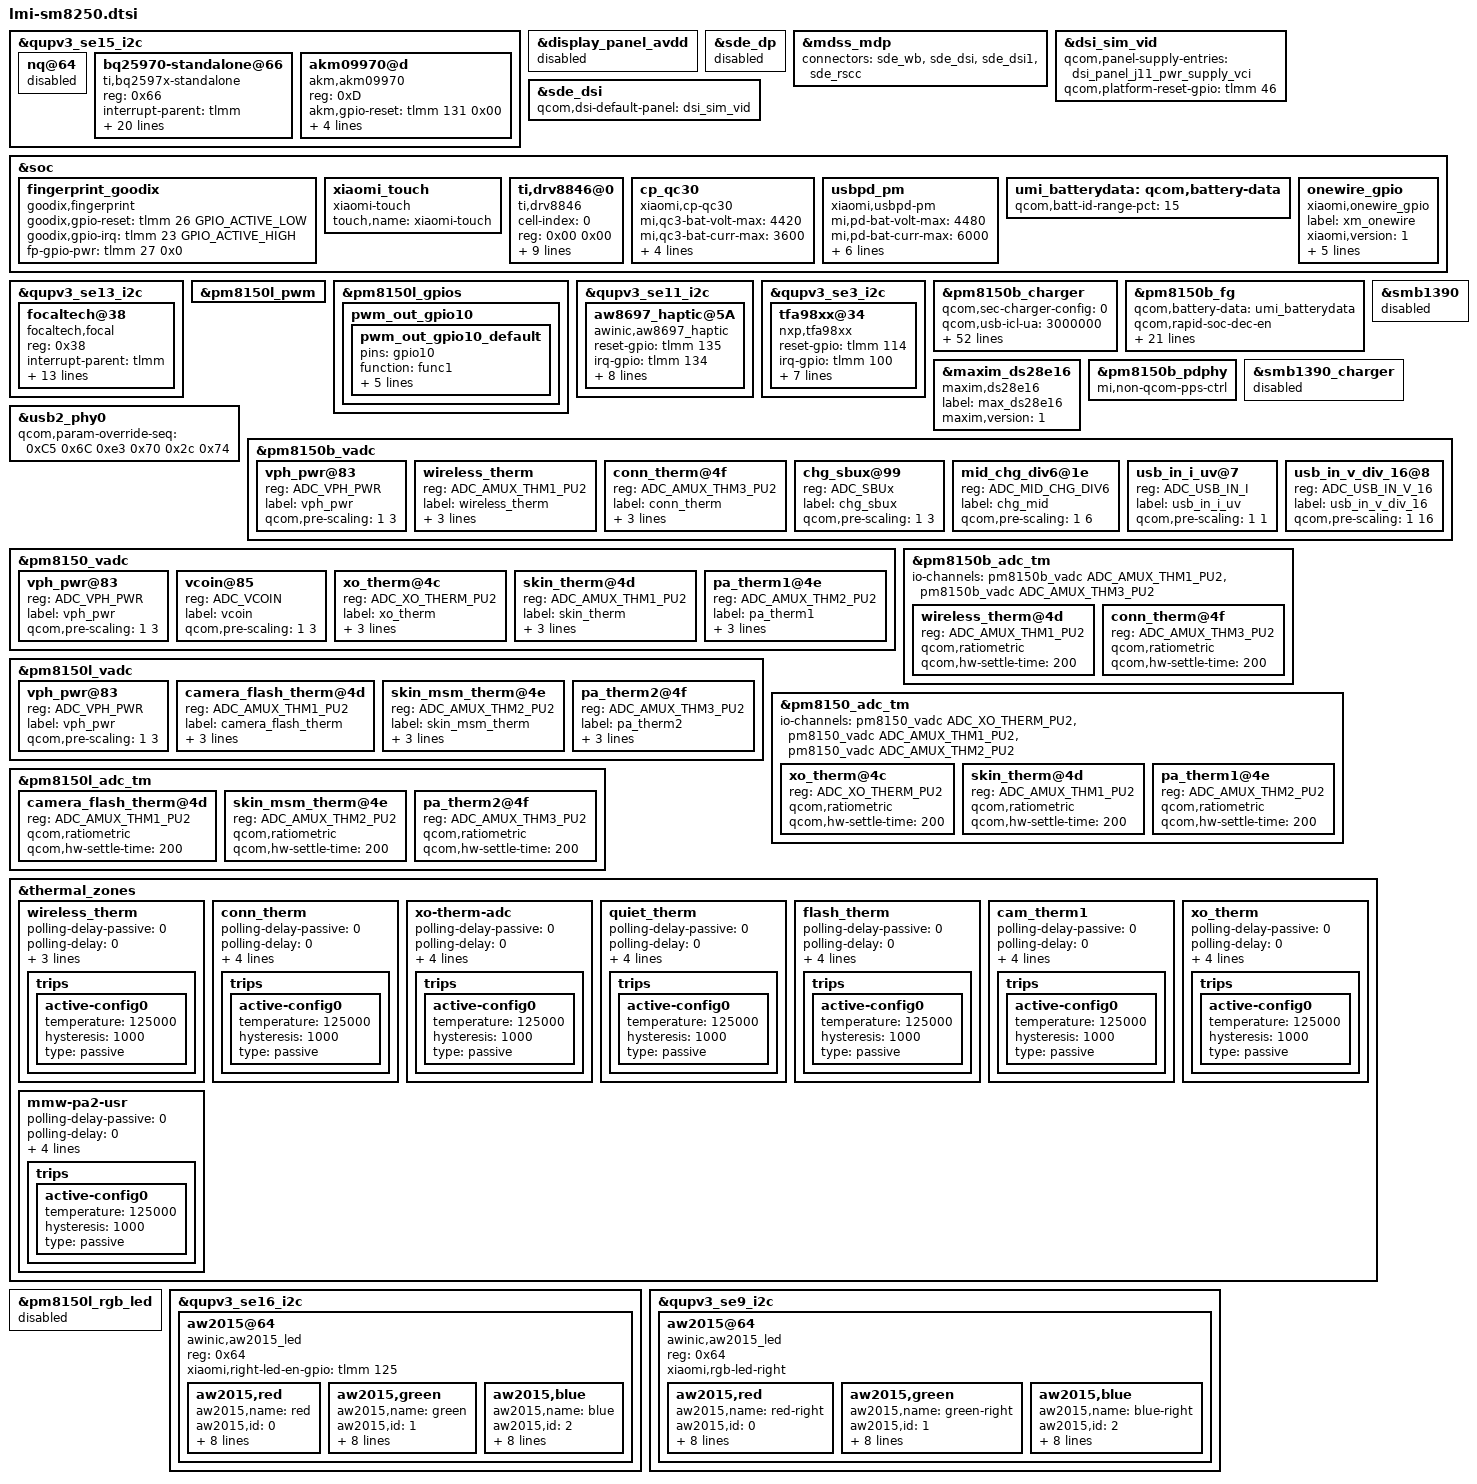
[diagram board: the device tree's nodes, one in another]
/*
this file is for attribution only of lmi
And public attribution of xiaomi platforms(like J1 and so and)
*/

#include "lmi-pinctrl.dtsi"
#include "xiaomi-sm8250-common.dtsi"
#include "lmi-audio-overlay.dtsi"

&qupv3_se15_i2c {
	status = "ok";
	nq@64 {
		status = "disabled";
	};
};

&display_panel_avdd {
	status = "disabled";
};

&sde_dp {
	status = "disabled";
};

&mdss_mdp {
	connectors = <&sde_wb &sde_dsi &sde_dsi1 &sde_rscc>;
};

&dsi_sim_vid {
	qcom,panel-supply-entries = <&dsi_panel_j11_pwr_supply_vci>;
	qcom,platform-reset-gpio = <&tlmm 46 0>;
};

&sde_dsi {
	/delete-property/ vdd-supply;
	/delete-property/ avdd-supply;
	qcom,dsi-default-panel = <&dsi_sim_vid>;
};

&soc {
    fingerprint_goodix {
		compatible = "goodix,fingerprint";
		goodix,gpio-reset = <&tlmm 26 GPIO_ACTIVE_LOW>;
		goodix,gpio-irq = <&tlmm 23 GPIO_ACTIVE_HIGH>;
		fp-gpio-pwr = <&tlmm 27 0x0>;
		status = "ok";
    };
};
&qupv3_se15_i2c {
	#address-cells = <1>;
	#size-cells = <0>;
	status = "ok";
	bq25970-standalone@66 {
		compatible = "ti,bq2597x-standalone";
		reg = <0x66>;
		interrupt-parent = <&tlmm>;
		interrupts = <157 0x2002>;
		pinctrl-names = "default";
		pinctrl-0 = <&bq2597x_master_int_default>;

		/*ti,bq2597x,bat-ovp-disable;*/
		ti,bq2597x,bat-ovp-alarm-disable;
		ti,bq2597x,bat-ocp-disable;
		ti,bq2597x,bat-ocp-alarm-disable;
		ti,bq2597x,bat-ucp-alarm-disable;
		ti,bq2597x,bat-ucp-disable;

		/*ti,bq2597x,bus-ovp-alarm-disable;
		ti,bq2597x,bus-ocp-disable;
		ti,bq2597x,bus-ocp-alarm-disable;*/
		ti,bq2597x,bat-therm-disable;
		ti,bq2597x,bus-therm-disable;
		ti,bq2597x,die-therm-disable;

		ti,bq2597x,bat-ovp-threshold = <4525>;
		ti,bq2597x,bat-ovp-alarm-threshold = <4525>;
		//ti,bq2597x,bat-ocp-threshold = <8000>;
		//ti,bq2597x,bat-ocp-alarm-threshold = <7500>;

		ti,bq2597x,bus-ovp-threshold = <12000>;
		ti,bq2597x,bus-ovp-alarm-threshold = <11000>;
		ti,bq2597x,bus-ocp-threshold = <3750>;
		ti,bq2597x,bus-ocp-alarm-threshold = <3500>;

		//ti,bq2597x,bat-ucp-alarm-threshold = <2000>;

		ti,bq2597x,bat-therm-threshold = <0x15>;/*4.1%*/
		ti,bq2597x,bus-therm-threshold = <0x15>;/*4.1%*/
		ti,bq2597x,die-therm-threshold = <145>;

		ti,bq2597x,ac-ovp-threshold = <14>;
		//ti,bq2597x,sense-resistor-mohm = <2>;
	};
};

&qupv3_se13_i2c {
	status = "ok";
	focaltech@38 {
		compatible = "focaltech,focal";
		reg = <0x38>;
		interrupt-parent = <&tlmm>;
		interrupts = <39 0x2002>;
		/* vddio-supply = <&pm8150a_l1>; */
		avdd-supply = <&pm8150a_l1>; //1v8
		focaltech,vdd-gpio = <&tlmm 72 0x0>;//3v
		focaltech,avdd-load = <300000>;
		focaltech,reset-gpio = <&tlmm 38 0x01>;
		focaltech,irq-gpio = <&tlmm 39 0x02>;
		focaltech,max-touch-number = <10>;
		focaltech,display-coords = <0 0 1080 2400>;
		focaltech,reset-when-resume;
		focaltech,lockdown-info-addr = <0x1E000>;
		focaltech,open-min = <2700>;
		pinctrl-names = "pmx_tp_active", "pmx_tp_suspend";
		pinctrl-0 = <&tp_active>;
		pinctrl-1 = <&tp_int_suspend &tp_reset_suspend>;
		/* focaltech,have-key; */
	};
};

&qupv3_se15_i2c {
        status = "ok";

        akm09970@d {
                compatible = "akm,akm09970";
                reg = <0xD>;
                akm,gpio-reset = <&tlmm 131 0x00>;
                akm,gpio-irq = <&tlmm 133 0x00>;
                vdd-supply = <&pm8150a_l8>;

                pinctrl-names = "akm09970_gpio_active", "akm09970_gpio_suspend";
                pinctrl-0 = <&akm_irq_active &akm_reset_active>;
                pinctrl-1 = <&akm_irq_suspend &akm_reset_suspend>;
                status = "ok";
        };
};

&pm8150l_pwm {
	status = "ok";
};

&soc{
	xiaomi_touch {
		compatible = "xiaomi-touch";
		status = "ok";
		touch,name = "xiaomi-touch";
	};

	ti,drv8846@0 {
		compatible = "ti,drv8846";
		cell-index = <0>;
		reg = <0x00 0x00>;
		pwms = <&pm8150l_pwm 1 1000000>;
		motor,gpio-mode0 = <&tlmm 158 0x00>;
		motor,gpio-mode1 = <&tlmm 154 0x00>;
		motor,gpio-sleep = <&tlmm 70 0x00>;
		motor,gpio-dir = <&tlmm 137 0x00>;
		motor,gpio-pwren = <&tlmm 153 0x00>;
		motor,step-mode = <2>;

		pinctrl-names = "default";
		pinctrl-0 = <&pwm_out_gpio10_default &motor_gpio_default>;
		status = "ok";
	};
};

&pm8150l_gpios {
	pwm_out_gpio10 {
		pwm_out_gpio10_default: pwm_out_gpio10_default {
			pins = "gpio10";
			function = "func1";
			bias-disable;
			power-source = <1>;
			output-low;
			qcom,drive-strength = <3>;
			drive-push-pull;
		};
	};
};

&qupv3_se11_i2c {
	status = "ok";
	aw8697_haptic@5A {
		compatible = "awinic,aw8697_haptic";
		reset-gpio = <&tlmm 135 0>;
		irq-gpio = <&tlmm 134 0>;
		vib_bst_vol_ram = < 0x11 >;
		vib_cont_drv_lev = < 106 >;
		vib_cont_drv_lvl_ov = < 106 >;
		vib_cont_td = < 0xef >;
		vib_tset = < 0x1a >;
		pinctrl-names = "aw8697_reset_reset","aw8697_reset_active","aw8697_interrupt_active";
		pinctrl-0 = <&msm_gpio_135>;
		pinctrl-1 = <&msm_gpio_135_output_high>;
		pinctrl-2 = <&msm_gpio_134>;
		status = "ok";
	};
};

&qupv3_se3_i2c {
	status = "ok";
	tfa98xx@34 {
		compatible = "nxp,tfa98xx";
		reset-gpio = <&tlmm 114 0>;
		irq-gpio = <&tlmm 100 0>;
		interrupt-parent = <&tlmm>;
		interrupts = <100 0>;
		interrupt-names = "smartpa_irq";
		pinctrl-names = "default", "sleep";
		pinctrl-0 = <&smartpa_int_active &smartpa_enable_active>;
		pinctrl-1 = <&smartpa_int_suspend &smartpa_enable_suspend>;
		reg = <0x34>;
		status = "ok";
	};
};

&pm8150b_charger {
	status = "ok";
	qcom,sec-charger-config = <0>;
	qcom,usb-icl-ua = <3000000>;
	qcom,fcc-max-ua = <6000000>;
	qcom,fv-max-uv = <4480000>;
	qcom,non-fcc-fv-max-uv = <4450000>;
	qcom,dc-icl-ua = <1000000>;
	qcom,auto-recharge-soc = <99>;
	qcom,chg-term-src = <1>;
	qcom,chg-term-current-ma = <(-220)>;
	//qcom,step-charging-enable;
	qcom,sw-jeita-enable;
	qcom,chg-warm-th= <480>;
	qcom,chg-cool-th= <150>;
	//qcom,suspend-input-on-debug-batt;
	qcom,usbpd-phandle = <&pm8150b_pdphy>;
	qcom,battery-data = <&umi_batterydata>;
	mi,six-pin-step-chg-params = <4250000  6000000
				4450000  5400000
				4480000  3680000>;
	mi,six-pin-step-chg;
	mi,six-pin-soc-th = <22>;
	mi,fcc-batt-unverify-ua = <2000000>;
	mi,support-ffc;
	qcom,lpd-disable;
	mi,use-bq-pump;
	qcom,disable-suspend-on-collapse;
	qcom,distinguish-qc-class-ab;
	qcom,support-conn-therm;
	vbus-disable-gpio = <&tlmm 152 GPIO_ACTIVE_HIGH>;
	pinctrl-names = "default", "vbus_disable_active", "vbus_disable_suspend";
	pinctrl-0 = <&vbus_disable_suspend>;
	pinctrl-1 = <&vbus_disable_active>;
	pinctrl-2 = <&vbus_disable_suspend>;
	io-channels = <&pm8150b_vadc ADC_USB_IN_V_16>,
			<&pm8150b_vadc ADC_MID_CHG_DIV6>,
			<&pm8150b_vadc ADC_USB_IN_I>,
			<&pm8150b_vadc ADC_SBUx>,
			<&pm8150b_vadc ADC_VPH_PWR>,
			<&pm8150b_vadc ADC_AMUX_THM3_PU2>,
			<&pm8150b_vadc ADC_CHG_TEMP>;
	io-channel-names = "usb_in_voltage",
			"mid_voltage",
			"usb_in_current",
			"sbux_res",
			"vph_voltage",
			"conn_temp",
			"chg_temp";
	qcom,thermal-mitigation = <3000000 2800000 2600000 2400000 2200000 2100000 2000000
				   1800000 1600000 1500000 1400000 1200000 1000000 900000
				   800000 500000>;
	qcom,thermal-mitigation-icl
				= <2800000 2700000 2600000 2400000 2200000 2100000 2000000
				   1800000 1600000 1500000 1400000 1300000 1200000 1100000
				   950000 750000>;
	qcom,thermal-mitigation-dcp
				= <1800000 1800000 1800000 1800000 1800000 1800000 1800000
				   1800000 1800000 1700000 1600000 1400000 1200000 1100000
				   1100000 1000000>;
	qcom,thermal-mitigation-qc2
				= <1500000 1500000 1500000 1500000 1450000 1400000 1350000
				   1300000 1150000 1100000 1000000 900000 850000 750000
				   650000 500000>;
	qcom,thermal-fcc-qc3-normal
				= <3200000 3000000 2800000 2600000 2500000 2400000 2300000
				   2200000 2100000 1800000 1600000 1400000 1200000 1000000
				   750000 750000>;
	qcom,thermal-fcc-qc3-cp
				= <4800000 4600000 4400000 4200000 4000000 3800000 3600000
				   3400000 3000000 2600000 2400000 2200000 2000000 1300000
				   1000000 700000>;
	qcom,thermal-fcc-qc3-classb-cp
				= <5100000 4700000 4300000 4000000 3600000 3500000 3400000
				   3400000 3400000 3200000 2500000 2200000 2000000 1300000
				   1000000 700000>;
	qcom,thermal-mitigation-pd-base
				= <3000000 2800000 2600000 2400000 2200000 2000000 1800000
				   1600000 1600000 1400000 1200000 1100000 1050000 1000000
				   950000 500000>;
	qcom,thermal-fcc-pps-bq
				= <6000000 5700000 5400000 5200000 4800000 4600000 4400000
				   4200000 3800000 3400000 3000000 2600000 2000000 1000000
				   700000 500000>;
};

&pm8150b_fg {
	qcom,battery-data = <&umi_batterydata>;
	qcom,rapid-soc-dec-en;
	qcom,five-pin-battery;
	qcom,soc-hi-res;
	qcom,sun-profile-only;
	qcom,soc_decimal_rate = <
		0  38
		10 35
		20 33
		30 33
		40 33
		50 33
		60 33
		70 30
		80 25
		90 20
		95 10 >;
	qcom,fg-sys-term-current = <(-300)>;
	qcom,fg-ffc-sys-term-current = <(-900)>;
	qcom,ki-coeff-low-chg = <315>;
	qcom,ki-coeff-med-chg = <183>;
	qcom,fg-cutoff-voltage = <3400>;
	qcom,fg-cutoff-current = <200>;
	qcom,fg-empty-voltage = <3100>;
	qcom,fg-batt-temp-hyst = <1>;
	qcom,fg-batt-temp-delta = <6>;
	qcom,soc-scale-vbatt-mv = <3600>;
	qcom,shutdown-delay-enable;
	qcom,fg-force-load-profile;
	qcom,ki-coeff-chg-med-hi-thresh-ma = <1000>;
	qcom,ki-coeff-chg-low-med-thresh-ma = <500>;
	qcom,ffc-ki-coeff-chg-med-hi-thresh-ma = <3900>;
	qcom,ffc-ki-coeff-chg-low-med-thresh-ma = <3500>;
};

&soc {
	cp_qc30 {
		compatible = "xiaomi,cp-qc30";
		status = "ok";
		mi,qc3-bat-volt-max = <4420>;
		mi,qc3-bat-curr-max = <3600>;
		mi,qc3-bus-volt-max = <12000>;
		mi,qc3-bus-curr-max = <2100>;
		mi,qc3-battery-warm-th = <480>;
		mi,use-qcom-gauge;
		//mi,cp-sec-enable;
	};

	usbpd_pm {
		compatible = "xiaomi,usbpd-pm";
		status = "ok";
		mi,pd-bat-volt-max = <4480>;
		mi,pd-bat-curr-max = <6000>;
		mi,pd-bus-volt-max = <12000>;
		mi,pd-bus-curr-max = <3000>;
		mi,pd-bus-curr-compensate  = <0>;
		mi,pd-non-ffc-bat-volt-max = <4450>;
		mi,pd-battery-warm-th = <480>;
		mi,use-qcom-gauge;
		//mi,cp-sec-enable;
	};

	umi_batterydata: qcom,battery-data {
		qcom,batt-id-range-pct = <15>;
		#include "fg-gen4-batterydata-lmi-sun-4700mah.dtsi"
	};

	onewire_gpio: onewire_gpio {
		compatible = "xiaomi,onewire_gpio";
		label = "xm_onewire";
		xiaomi,version = <1>;
		xiaomi,ow_gpio = <&tlmm 9 0x00>;
		mi,onewire-gpio-cfg-addr = <0x0F909000 0x4>;
		xiaomi,gpio_number = <9>;
		pinctrl-names = "onewire_active", "onewire_sleep";
		pinctrl-0 = <&onewire_gpio_active>;
		pinctrl-1 = <&onewire_gpio_sleep>;
		status = "ok";
	};
};

&maxim_ds28e16 {
	compatible = "maxim,ds28e16";
	label = "max_ds28e16";
	maxim,version = <1>;
	status = "ok";
};

&pm8150b_pdphy {
	mi,non-qcom-pps-ctrl;
};

&smb1390 {
	status = "disabled";
};

&smb1390_charger {
	status = "disabled";
};

&usb2_phy0 {
	qcom,param-override-seq =
		<0xC5 0x6C
		 0xe3 0x70
		 0x2c 0x74>;
};

&pm8150b_vadc {
	#address-cells = <1>;
	#size-cells = <0>;

	vph_pwr@83 {
		reg = <ADC_VPH_PWR>;
		label = "vph_pwr";
		qcom,pre-scaling = <1 3>;
	};

	wireless_therm {
		reg = <ADC_AMUX_THM1_PU2>;
		label = "wireless_therm";
		qcom,ratiometric;
		qcom,hw-settle-time = <200>;
		qcom,pre-scaling = <1 1>;
	};

	conn_therm@4f {
		reg = <ADC_AMUX_THM3_PU2>;
		label = "conn_therm";
		qcom,ratiometric;
		qcom,hw-settle-time = <200>;
		qcom,pre-scaling = <1 1>;
	};

	chg_sbux@99 {
		reg = <ADC_SBUx>;
		label = "chg_sbux";
		qcom,pre-scaling = <1 3>;
	};

	mid_chg_div6@1e {
		reg = <ADC_MID_CHG_DIV6>;
		label = "chg_mid";
		qcom,pre-scaling = <1 6>;
	};

	usb_in_i_uv@7 {
		reg = <ADC_USB_IN_I>;
		label = "usb_in_i_uv";
		qcom,pre-scaling = <1 1>;
	};

	usb_in_v_div_16@8 {
		reg = <ADC_USB_IN_V_16>;
		label = "usb_in_v_div_16";
		qcom,pre-scaling = <1 16>;
	};
};

&pm8150_vadc {
	#address-cells = <1>;
	#size-cells = <0>;

	vph_pwr@83 {
		reg = <ADC_VPH_PWR>;
		label = "vph_pwr";
		qcom,pre-scaling = <1 3>;
	};

	vcoin@85 {
		reg = <ADC_VCOIN>;
		label = "vcoin";
		qcom,pre-scaling = <1 3>;
	};

	xo_therm@4c {
		reg = <ADC_XO_THERM_PU2>;
		label = "xo_therm";
		qcom,ratiometric;
		qcom,hw-settle-time = <200>;
		qcom,pre-scaling = <1 1>;
	};

	skin_therm@4d {
		reg = <ADC_AMUX_THM1_PU2>;
		label = "skin_therm";
		qcom,ratiometric;
		qcom,hw-settle-time = <200>;
		qcom,pre-scaling = <1 1>;
	};

	pa_therm1@4e {
		reg = <ADC_AMUX_THM2_PU2>;
		label = "pa_therm1";
		qcom,ratiometric;
		qcom,hw-settle-time = <200>;
		qcom,pre-scaling = <1 1>;
	};
};

&pm8150l_vadc {
	#address-cells = <1>;
	#size-cells = <0>;

	vph_pwr@83 {
		reg = <ADC_VPH_PWR>;
		label = "vph_pwr";
		qcom,pre-scaling = <1 3>;
	};

	camera_flash_therm@4d {
		reg = <ADC_AMUX_THM1_PU2>;
		label = "camera_flash_therm";
		qcom,ratiometric;
		qcom,hw-settle-time = <200>;
		qcom,pre-scaling = <1 1>;
	};

	skin_msm_therm@4e {
		reg = <ADC_AMUX_THM2_PU2>;
		label = "skin_msm_therm";
		qcom,ratiometric;
		qcom,hw-settle-time = <200>;
		qcom,pre-scaling = <1 1>;
	};

	pa_therm2@4f {
		reg = <ADC_AMUX_THM3_PU2>;
		label = "pa_therm2";
		qcom,ratiometric;
		qcom,hw-settle-time = <200>;
		qcom,pre-scaling = <1 1>;
	};
};

&pm8150b_adc_tm {
	#address-cells = <1>;
	#size-cells = <0>;

	io-channels = <&pm8150b_vadc ADC_AMUX_THM1_PU2>,
			<&pm8150b_vadc ADC_AMUX_THM3_PU2>;

	wireless_therm@4d {
		reg = <ADC_AMUX_THM1_PU2>;
		qcom,ratiometric;
		qcom,hw-settle-time = <200>;
	};

	conn_therm@4f {
		reg = <ADC_AMUX_THM3_PU2>;
		qcom,ratiometric;
		qcom,hw-settle-time = <200>;
	};
};

&pm8150_adc_tm {
	#address-cells = <1>;
	#size-cells = <0>;

	io-channels = <&pm8150_vadc ADC_XO_THERM_PU2>,
			<&pm8150_vadc ADC_AMUX_THM1_PU2>,
			<&pm8150_vadc ADC_AMUX_THM2_PU2>;

	xo_therm@4c {
		reg = <ADC_XO_THERM_PU2>;
		qcom,ratiometric;
		qcom,hw-settle-time = <200>;
	};

	skin_therm@4d {
		reg = <ADC_AMUX_THM1_PU2>;
		qcom,ratiometric;
		qcom,hw-settle-time = <200>;
	};

	pa_therm1@4e {
		reg = <ADC_AMUX_THM2_PU2>;
		qcom,ratiometric;
		qcom,hw-settle-time = <200>;
	};
};

&pm8150l_adc_tm {
	#address-cells = <1>;
	#size-cells = <0>;

	camera_flash_therm@4d {
		reg = <ADC_AMUX_THM1_PU2>;
		qcom,ratiometric;
		qcom,hw-settle-time = <200>;
	};

	skin_msm_therm@4e {
		reg = <ADC_AMUX_THM2_PU2>;
		qcom,ratiometric;
		qcom,hw-settle-time = <200>;
	};

	pa_therm2@4f {
		reg = <ADC_AMUX_THM3_PU2>;
		qcom,ratiometric;
		qcom,hw-settle-time = <200>;
	};
};

&thermal_zones {
	wireless_therm {//place close to wireless charge RX
		polling-delay-passive = <0>;
		polling-delay = <0>;
		thermal-governor = "user_space";
		thermal-sensors = <&pm8150b_adc_tm ADC_AMUX_THM1_PU2>;
		trips {
			active-config0 {
				temperature = <125000>;
				hysteresis = <1000>;
				type = "passive";
			};
		};
	};

	conn_therm {//place close to type-c connector
		polling-delay-passive = <0>;
		polling-delay = <0>;
		thermal-governor = "user_space";
		thermal-sensors = <&pm8150b_adc_tm ADC_AMUX_THM3_PU2>;
		wake-capable-sensor;
		trips {
			active-config0 {
				temperature = <125000>;
				hysteresis = <1000>;
				type = "passive";
			};
		};
	};

	xo-therm-adc {
		polling-delay-passive = <0>;
		polling-delay = <0>;
		thermal-governor = "user_space";
		thermal-sensors = <&pm8150_adc_tm ADC_XO_THERM_PU2>;
		wake-capable-sensor;
		trips {
			active-config0 {
				temperature = <125000>;
				hysteresis = <1000>;
				type = "passive";
			};
		};
	};

	quiet_therm {//place close to a cool place
		polling-delay-passive = <0>;
		polling-delay = <0>;
		thermal-governor = "user_space";
		thermal-sensors = <&pm8150_adc_tm ADC_AMUX_THM1_PU2>;
		wake-capable-sensor;
		trips {
			active-config0 {
				temperature = <125000>;
				hysteresis = <1000>;
				type = "passive";
			};
		};
	};

	flash_therm {//place close to flash fpc
		polling-delay-passive = <0>;
		polling-delay = <0>;
		thermal-governor = "user_space";
		thermal-sensors = <&pm8150_adc_tm ADC_AMUX_THM2_PU2>;
		wake-capable-sensor;
		trips {
			active-config0 {
				temperature = <125000>;
				hysteresis = <1000>;
				type = "passive";
			};
		};
	};

	cam_therm1 {//place close to rear camera
		polling-delay-passive = <0>;
		polling-delay = <0>;
		thermal-governor = "user_space";
		thermal-sensors = <&pm8150l_adc_tm ADC_AMUX_THM1_PU2>;
		wake-capable-sensor;
		trips {
			active-config0 {
				temperature = <125000>;
				hysteresis = <1000>;
				type = "passive";
			};
		};
	};

	xo_therm {//place close to sm8250 hot place
		polling-delay-passive = <0>;
		polling-delay = <0>;
		thermal-governor = "user_space";
		thermal-sensors = <&pm8150l_adc_tm ADC_AMUX_THM2_PU2>;
		wake-capable-sensor;
		trips {
			active-config0 {
				temperature = <125000>;
				hysteresis = <1000>;
				type = "passive";
			};
		};
	};

	mmw-pa2-usr {
		polling-delay-passive = <0>;
		polling-delay = <0>;
		thermal-governor = "user_space";
		thermal-sensors = <&pm8150l_adc_tm ADC_AMUX_THM3_PU2>;
		wake-capable-sensor;
		trips {
			active-config0 {
				temperature = <125000>;
				hysteresis = <1000>;
				type = "passive";
			};
		};
	};
};

&pm8150l_rgb_led {
	status = "disabled";
};

&qupv3_se16_i2c {
	status = "ok";
	aw2015@64 {
		compatible = "awinic,aw2015_led";
		reg = <0x64>;

		xiaomi,right-led-en-gpio = <&tlmm 125 0>;

		aw2015,red {
			aw2015,name = "red";
			aw2015,id = <0>;
			aw2015,imax = <0>;
			aw2015,led-current = <255>;
			aw2015,max-brightness = <30>;
			aw2015,rise-time-ms = <6>;
			aw2015,hold-time-ms = <0>;
			aw2015,fall-time-ms = <6>;
			aw2015,off-time-ms = <4>;
			linux,default-trigger = "timer";
		};

		aw2015,green {
			aw2015,name = "green";
			aw2015,id = <1>;
			aw2015,imax = <0>;
			aw2015,led-current = <255>;
			aw2015,max-brightness = <30>;
			aw2015,rise-time-ms = <6>;
			aw2015,hold-time-ms = <0>;
			aw2015,fall-time-ms = <6>;
			aw2015,off-time-ms = <4>;
			linux,default-trigger = "timer";
		};

		aw2015,blue {
			aw2015,name = "blue";
			aw2015,id = <2>;
			aw2015,imax = <0>;
			aw2015,led-current = <255>;
			aw2015,max-brightness = <30>;
			aw2015,rise-time-ms = <6>;
			aw2015,hold-time-ms = <0>;
			aw2015,fall-time-ms = <6>;
			aw2015,off-time-ms = <4>;
			linux,default-trigger = "timer";
		};
	};
};

&qupv3_se9_i2c {
	status = "ok";
	aw2015@64 {
		compatible = "awinic,aw2015_led";
		reg = <0x64>;

		xiaomi,rgb-led-right;

		aw2015,red {
			aw2015,name = "red-right";
			aw2015,id = <0>;
			aw2015,imax = <1>;
			aw2015,led-current = <255>;
			aw2015,max-brightness = <255>;
			aw2015,rise-time-ms = <6>;
			aw2015,hold-time-ms = <0>;
			aw2015,fall-time-ms = <6>;
			aw2015,off-time-ms = <4>;
			linux,default-trigger = "timer";
		};

		aw2015,green {
			aw2015,name = "green-right";
			aw2015,id = <1>;
			aw2015,imax = <1>;
			aw2015,led-current = <255>;
			aw2015,max-brightness = <255>;
			aw2015,rise-time-ms = <6>;
			aw2015,hold-time-ms = <0>;
			aw2015,fall-time-ms = <6>;
			aw2015,off-time-ms = <4>;
			linux,default-trigger = "timer";
		};

		aw2015,blue {
			aw2015,name = "blue-right";
			aw2015,id = <2>;
			aw2015,imax = <1>;
			aw2015,led-current = <255>;
			aw2015,max-brightness = <255>;
			aw2015,rise-time-ms = <6>;
			aw2015,hold-time-ms = <0>;
			aw2015,fall-time-ms = <6>;
			aw2015,off-time-ms = <4>;
			linux,default-trigger = "timer";
		};
	};
};
